AUTOSAR XML (schema 440)
package /EPS_System
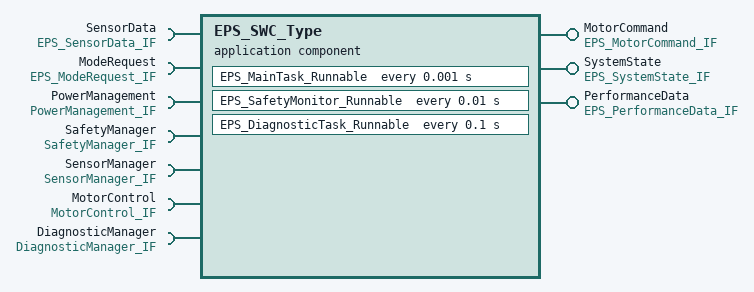
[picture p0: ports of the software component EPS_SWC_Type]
  application sw component type EPS_SWC_Type: category=APPLICATION_LEVEL
    require port SensorData: required-interface=EPS_SensorData_IF
    provide port MotorCommand: provided-interface=EPS_MotorCommand_IF
    provide port SystemState: provided-interface=EPS_SystemState_IF
    provide port PerformanceData: provided-interface=EPS_PerformanceData_IF
    6 x require port:
      ModeRequest: required-interface=EPS_ModeRequest_IF
      PowerManagement: required-interface=PowerManagement_IF
      SafetyManager: required-interface=SafetyManager_IF
      SensorManager: required-interface=SensorManager_IF
      MotorControl: required-interface=MotorControl_IF
      DiagnosticManager: required-interface=DiagnosticManager_IF
    behavior EPS_SWC_InternalBehavior
      6 x runnable:
        EPS_Init_Runnable
        EPS_MainTask_Runnable: minimum-start-interval=0.001
          data-read-access:
            access SensorData_Read: accessed-variable=SensorData.SensorData
          data-write-access:
            access MotorCommand_Write: accessed-variable=MotorCommand.MotorCommand
        EPS_SafetyMonitor_Runnable: minimum-start-interval=0.01
        EPS_DiagnosticTask_Runnable: minimum-start-interval=0.1
        EPS_ModeRequest_Runnable
        EPS_Shutdown_Runnable
      init event EPS_InitEvent: start-on-event=EPS_Init_Runnable
      timing event EPS_MainTask_TimingEvent: start-on-event=EPS_MainTask_Runnable, period=0.001
      timing event EPS_SafetyMonitor_TimingEvent: start-on-event=EPS_SafetyMonitor_Runnable, period=0.01
      timing event EPS_DiagnosticTask_TimingEvent: start-on-event=EPS_DiagnosticTask_Runnable, period=0.1
      data received event EPS_ModeRequest_DataReceivedEvent: start-on-event=EPS_ModeRequest_Runnable, data=ModeRequest.ModeRequest
      4 x inter runnable variable:
        EPS_IRV_SensorData: implementation-data-type=EPS_SensorData_T
        EPS_IRV_AssistanceParams: implementation-data-type=EPS_AssistanceParams_T
        EPS_IRV_MotorCommand: implementation-data-type=EPS_MotorCommand_T
        EPS_IRV_SystemState: implementation-data-type=EPS_SystemState_T
package /EPS_System/Interfaces
  5 x sender receiver interface:
    EPS_SensorData_IF
      data SensorData: implementation-data-type=EPS_SensorData_T
    EPS_MotorCommand_IF
      data MotorCommand: implementation-data-type=EPS_MotorCommand_T
    EPS_SystemState_IF
      data SystemState: implementation-data-type=EPS_SystemState_T
    EPS_PerformanceData_IF
      data PerformanceData: implementation-data-type=EPS_PerformanceData_T
    EPS_ModeRequest_IF
      data ModeRequest: implementation-data-type=EPS_OperatingMode_T
  client server interface PowerManagement_IF
    operation Init: possible-error=E_NOT_OK
    operation EnterSleep
    operation GetConsumption
      arg consumption: type=float32, direction=OUT
    error E_NOT_OK: error-code=1
package /EPS_System/DataTypes
  impl type EPS_OperatingMode_T: category=PRIMITIVE, base-type=uint8
  impl type EPS_SystemStatus_T: category=PRIMITIVE, base-type=uint8
  impl type EPS_SensorData_T: category=STRUCTURE
    4 x element, all with category=PRIMITIVE:
      DriverTorque_Nm: base-type=float32
      SteeringAngle_Deg: base-type=float32
      VehicleSpeed_KmH: base-type=float32
      DataValid: base-type=boolean
